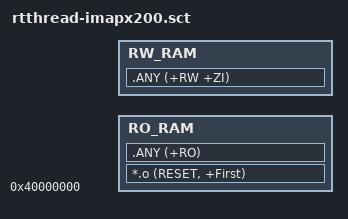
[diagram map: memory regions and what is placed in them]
; *************************************************************
; *** Scatter-Loading Description File generated by uVision ***
; *************************************************************

LR_ROM1 0x40000000 0x10000000  {    ; load region size_region
  RO_RAM  +0  {  ; load address = execution address
   *.o (RESET, +First)
   ;Start.o
   ;*(InRoot$$Sections)
   .ANY (+RO)
  }
  RW_RAM +0  {  ; RW data
   .ANY (+RW +ZI)
  }

}

